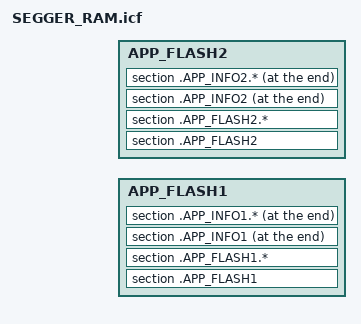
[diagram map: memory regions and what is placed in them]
/*********************************************************************
*                    SEGGER Microcontroller GmbH                     *
*                        The Embedded Experts                        *
**********************************************************************
*                                                                    *
*            (c) 2014 - 2022 SEGGER Microcontroller GmbH             *
*                                                                    *
*       www.segger.com     Support: support@segger.com               *
*                                                                    *
**********************************************************************
*                                                                    *
* All rights reserved.                                               *
*                                                                    *
* Redistribution and use in source and binary forms, with or         *
* without modification, are permitted provided that the following    *
* condition is met:                                                  *
*                                                                    *
* - Redistributions of source code must retain the above copyright   *
*   notice, this condition and the following disclaimer.             *
*                                                                    *
* THIS SOFTWARE IS PROVIDED BY THE COPYRIGHT HOLDERS AND             *
* CONTRIBUTORS "AS IS" AND ANY EXPRESS OR IMPLIED WARRANTIES,        *
* INCLUDING, BUT NOT LIMITED TO, THE IMPLIED WARRANTIES OF           *
* MERCHANTABILITY AND FITNESS FOR A PARTICULAR PURPOSE ARE           *
* DISCLAIMED. IN NO EVENT SHALL SEGGER Microcontroller BE LIABLE FOR *
* ANY DIRECT, INDIRECT, INCIDENTAL, SPECIAL, EXEMPLARY, OR           *
* CONSEQUENTIAL DAMAGES (INCLUDING, BUT NOT LIMITED TO, PROCUREMENT  *
* OF SUBSTITUTE GOODS OR SERVICES; LOSS OF USE, DATA, OR PROFITS;    *
* OR BUSINESS INTERRUPTION) HOWEVER CAUSED AND ON ANY THEORY OF      *
* LIABILITY, WHETHER IN CONTRACT, STRICT LIABILITY, OR TORT          *
* (INCLUDING NEGLIGENCE OR OTHERWISE) ARISING IN ANY WAY OUT OF THE  *
* USE OF THIS SOFTWARE, EVEN IF ADVISED OF THE POSSIBILITY OF SUCH   *
* DAMAGE.                                                            *
*                                                                    *
**********************************************************************
-------------------------- END-OF-HEADER -----------------------------

File    : SEGGER_RAM.icf
Purpose : Generic linker script for application placement in RAM
          (to be copied to RAM by bootloader or debugger)
          for use with the SEGGER Linker.
Literature:
  [1]  SEGGER Linker User Guide (https://www.segger.com/doc/UM20005_Linker.html)
  [2]  SEGGER Linker Section Placement (https://wiki.segger.com/SEGGER_Linker_Script_Files)
*/

define memory with size = 4G;

//
// Combined regions per memory type
//
//define region AXI_RAM   = [from 0x24000000 size 0x30000];
//define region ITCM = [from 0x00000000 size 0x30000];
//define region DTCM = [from 0x20000000 size 0x20000];
//define region RAM_D2 = [from 0x30000000 size 0x8000];


define region APP_FLASH1 =  [from 0x08020000 size 0x30000];
define region APP_FLASH2 = [from 0x08060000 size 0x30000];

define region CONFIG_A = [from 0x080A0000 size 0x20000];
define region CONFIG_B = [from 0x080C0000 size 0x20000];
define region CONFIG_C = [from 0x080E0000 size 0x20000];




//
// Block definitions
//
define block ctors                          { section .ctors,     section .ctors.*, block with         alphabetical order { init_array } };
define block dtors                          { section .dtors,     section .dtors.*, block with reverse alphabetical order { fini_array } };
define block exidx                          { section .ARM.exidx, section .ARM.exidx.* };
define block tbss                           { section .tbss,      section .tbss.*  };
define block tdata                          { section .tdata,     section .tdata.* };
define block tls with fixed order           { block tbss, block tdata };
define block tdata_load                     { copy of block tdata };
define block heap  with auto size = __HEAPSIZE__,  alignment = 8, /* fill =0x00, */ readwrite access { };
define block stack with      size = __STACKSIZE__, alignment = 8, /* fill =0xCD, */ readwrite access { };
//
// Explicit initialization settings for sections
// Packing options for initialize by copy: packing=auto/lzss/zpak/packbits
//
do not initialize                           { section .non_init, section .non_init.*, section .*.non_init, section .*.non_init.* };
do not initialize                           { section .no_init, section .no_init.*, section .*.no_init, section .*.no_init.* };   // Legacy sections, kept for backwards compatibility
do not initialize                           { section .noinit, section .noinit.*, section .*.noinit, section .*.noinit.* };       // Legacy sections, used by some SDKs/HALs
do not initialize                           { section .vectors_ram };
initialize by copy with packing=auto        { section .data, section .data.*, section .*.data, section .*.data.* };               // Static data sections
initialize by copy with packing=auto        { section .fast, section .fast.*, section .*.fast, section .*.fast.* };               // "RAM Code" sections


#define USES_ALLOC_FUNC                                   \
  linked symbol malloc || linked symbol aligned_alloc ||  \
  linked symbol calloc || linked symbol realloc

initialize by calling __SEGGER_init_heap if USES_ALLOC_FUNC { block heap };                        // Init the heap if one is required
initialize by calling __SEGGER_init_ctors    { block ctors };                                      // Call constructors for global objects which need to be constructed before reaching main (if any). Make sure this is done after setting up heap.

//assert with warning "free() linked into application but there are no calls to an allocation function!" {
//  linked symbol free => USES_ALLOC_FUNC
//};

assert with error "heap is too small!"              { USES_ALLOC_FUNC => size  of block heap >= 48 };
assert with error "heap size not a multiple of 8!"  { USES_ALLOC_FUNC => size  of block heap % 8 == 0 };
assert with error "heap not correctly aligned!"     { USES_ALLOC_FUNC => start of block heap % 8 == 0 };


//
// Explicit placement in RAMn
//
place in AXI_RAM                               { section .AXI_RAM, section .AXI_RAM.* };
place in ITCM                               { section .ITCM, section .ITCM.* };
place in DTCM                               { section .DTCM, section .DTCM.* };
place in RAM_D2                               { section .RAM_D2, section .RAM_D2.* };
place in RAM_D4                               { section .RAM_D4, section .RAM_D4.* };

place in APP_FLASH1                               { section .APP_FLASH1, section .APP_FLASH1.* };
place in APP_FLASH2                               { section .APP_FLASH2, section .APP_FLASH2.* };

place at end of APP_FLASH1                         { section .APP_INFO1, section .APP_INFO1.*  }; 
place at end of APP_FLASH2                         { section .APP_INFO2 , section .APP_INFO2.*}; 

place at end of ITCM                               { section .APP_INFO_ACT , section .APP_INFO_ACT.*}; 

//
// RAM Placement
//
place at start of ITCM                       { section .vectors };                                   // Vector table section
place in ITCM with minimum size order        { block tdata_load,                                     // Thread-local-storage load image
                                              block exidx,                                          // ARM exception unwinding block
                                              block ctors,                                          // Constructors block
                                              block dtors,                                          // Destructors block
                                              readexec,                                              // Catch-all for (readonly) executable code (e.g. .text)
                                              readonly                                             // Catch-all for readonly data (e.g. .rodata, .srodata)

                                            };
                                             
place in ITCM with auto order                { section .fast, section .fast.*,                       // "ramfunc" section
                                            };
place in DTCM with auto order                {block tls,                                            // Thread-local-storage block
                                              readwrite,                                            // Catch-all for initialized/uninitialized data sections (e.g. .data, .noinit)
                                              zeroinit                                              // Catch-all for zero-initialized data sections (e.g. .bss)
                                              
                                              
};

place in DTCM                                { block heap };                                         // Heap reserved block
place at end of DTCM                         { block stack };                                        // Stack reserved block at the end
